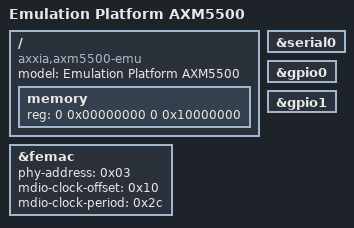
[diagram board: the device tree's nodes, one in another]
/*
 * arch/arm/boot/dts/axm5504-emulation.dts
 *
 * Copyright (C) 2018 INTEL
 *
 * This program is free software; you can redistribute it and/or modify
 * it under the terms of the GNU General Public License as published by
 * the Free Software Foundation; either version 2 of the License, or
 * (at your option) any later version.
 */

/dts-v1/;

/memreserve/ 0x00000000 0x00400000;

/include/ "axm55xx.dtsi"
/include/ "axm5504-cpus.dtsi"

/ {
	model = "Emulation Platform AXM5500";
	compatible = "axxia,axm5500-emu", "axxia,axm5500";

	memory {
		device_type = "memory";
		reg = <0 0x00000000 0 0x10000000>;
	};
};

&femac {
	status = "okay";
	phy-address = <0x03>;
	mdio-clock-offset = <0x10>;
	mdio-clock-period = <0x2c>;
};

&serial0 {
	status = "okay";
};

&gpio0 {
	status = "okay";
};

&gpio1 {
	status = "okay";
};
